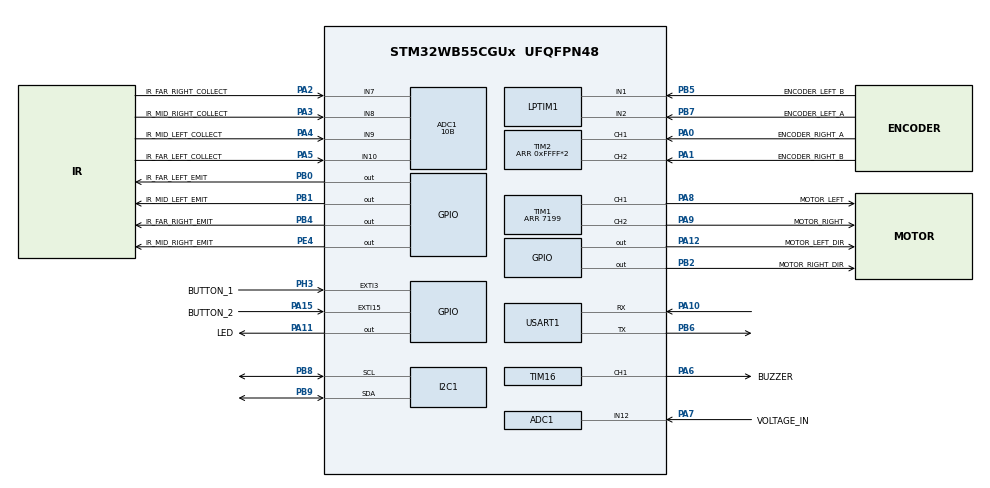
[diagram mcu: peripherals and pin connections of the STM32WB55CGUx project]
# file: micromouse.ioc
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ADC1.Channel-10\#ChannelRegularConversion=ADC_CHANNEL_7
ADC1.Channel-14\#ChannelRegularConversion=ADC_CHANNEL_8
ADC1.Channel-15\#ChannelRegularConversion=ADC_CHANNEL_9
ADC1.Channel-16\#ChannelRegularConversion=ADC_CHANNEL_10
ADC1.Channel-17\#ChannelRegularConversion=ADC_CHANNEL_12
ADC1.NbrOfConversion=5
ADC1.NbrOfConversionFlag=1
ADC1.OffsetNumber-10\#ChannelRegularConversion=ADC_OFFSET_NONE
ADC1.OffsetNumber-14\#ChannelRegularConversion=ADC_OFFSET_NONE
ADC1.OffsetNumber-15\#ChannelRegularConversion=ADC_OFFSET_NONE
ADC1.OffsetNumber-16\#ChannelRegularConversion=ADC_OFFSET_NONE
ADC1.OffsetNumber-17\#ChannelRegularConversion=ADC_OFFSET_NONE
ADC1.Rank-10\#ChannelRegularConversion=1
ADC1.Rank-14\#ChannelRegularConversion=2
ADC1.Rank-15\#ChannelRegularConversion=3
ADC1.Rank-16\#ChannelRegularConversion=4
ADC1.Rank-17\#ChannelRegularConversion=5
ADC1.Resolution=ADC_RESOLUTION_10B
ADC1.SamplingTime-10\#ChannelRegularConversion=ADC_SAMPLETIME_2CYCLES_5
ADC1.SamplingTime-14\#ChannelRegularConversion=ADC_SAMPLETIME_2CYCLES_5
ADC1.SamplingTime-15\#ChannelRegularConversion=ADC_SAMPLETIME_2CYCLES_5
ADC1.SamplingTime-16\#ChannelRegularConversion=ADC_SAMPLETIME_2CYCLES_5
ADC1.SamplingTime-17\#ChannelRegularConversion=ADC_SAMPLETIME_2CYCLES_5
ADC1.master=1
Dma.ADC1.0.Direction=DMA_PERIPH_TO_MEMORY
Dma.ADC1.0.EventEnable=DISABLE
Dma.ADC1.0.Instance=DMA1_Channel2
Dma.ADC1.0.MemDataAlignment=DMA_MDATAALIGN_HALFWORD
Dma.ADC1.0.MemInc=DMA_MINC_ENABLE
Dma.ADC1.0.Mode=DMA_NORMAL
Dma.ADC1.0.PeriphDataAlignment=DMA_PDATAALIGN_HALFWORD
Dma.ADC1.0.PeriphInc=DMA_PINC_DISABLE
Dma.ADC1.0.Polarity=HAL_DMAMUX_REQ_GEN_RISING
Dma.ADC1.0.Priority=DMA_PRIORITY_LOW
Dma.ADC1.0.RequestNumber=1
Dma.ADC1.0.SignalID=NONE
Dma.ADC1.0.SyncEnable=DISABLE
Dma.ADC1.0.SyncPolarity=HAL_DMAMUX_SYNC_NO_EVENT
Dma.ADC1.0.SyncRequestNumber=1
Dma.ADC1.0.SyncSignalID=NONE
Dma.I2C1_RX.1.Direction=DMA_PERIPH_TO_MEMORY
Dma.I2C1_RX.1.EventEnable=DISABLE
Dma.I2C1_RX.1.Instance=DMA1_Channel1
Dma.I2C1_RX.1.MemDataAlignment=DMA_MDATAALIGN_BYTE
Dma.I2C1_RX.1.MemInc=DMA_MINC_ENABLE
Dma.I2C1_RX.1.Mode=DMA_NORMAL
Dma.I2C1_RX.1.PeriphDataAlignment=DMA_PDATAALIGN_BYTE
Dma.I2C1_RX.1.PeriphInc=DMA_PINC_DISABLE
Dma.I2C1_RX.1.Polarity=HAL_DMAMUX_REQ_GEN_RISING
Dma.I2C1_RX.1.Priority=DMA_PRIORITY_HIGH
Dma.I2C1_RX.1.RequestNumber=1
Dma.I2C1_RX.1.SignalID=NONE
Dma.I2C1_RX.1.SyncEnable=DISABLE
Dma.I2C1_RX.1.SyncPolarity=HAL_DMAMUX_SYNC_NO_EVENT
Dma.I2C1_RX.1.SyncRequestNumber=1
Dma.I2C1_RX.1.SyncSignalID=NONE
Dma.Request0=ADC1
Dma.Request1=I2C1_RX
I2C1.I2C_Fall_Time=200
I2C1.I2C_Rise_Time=700
I2C1.Timing=0x30F23E4F
LPTIM1.ULPClockPolarity=LPTIM_CLOCKPOLARITY_RISING
Mcu.Family=STM32WB
Mcu.Name=STM32WB55CGUx
Mcu.Package=UFQFPN48
NVIC.DMA1_Channel1_IRQn=true\:0\:0\:false\:false\:true\:false\:true\:true
NVIC.DMA1_Channel2_IRQn=true\:0\:0\:false\:false\:true\:false\:true\:true
NVIC.EXTI15_10_IRQn=true\:0\:0\:false\:false\:true\:true\:true\:true
NVIC.EXTI3_IRQn=true\:0\:0\:false\:false\:true\:true\:true\:true
NVIC.HSEM_IRQn=true\:0\:0\:false\:false\:true\:false\:true\:true
NVIC.I2C1_ER_IRQn=true\:0\:0\:false\:false\:true\:true\:true\:true
NVIC.I2C1_EV_IRQn=true\:0\:0\:false\:false\:true\:true\:true\:true
NVIC.IPCC_C1_RX_IRQn=true\:0\:0\:false\:false\:true\:true\:true\:true
NVIC.IPCC_C1_TX_IRQn=true\:0\:0\:false\:false\:true\:true\:true\:true
NVIC.PriorityGroup=NVIC_PRIORITYGROUP_4
NVIC.RTC_WKUP_IRQn=true\:0\:0\:false\:false\:true\:true\:true\:true
NVIC.TIM1_TRG_COM_TIM17_IRQn=true\:15\:0\:false\:false\:true\:false\:true\:true
OSC_IN.Mode=HSE-External-Oscillator
OSC_IN.Signal=RCC_OSC_IN
OSC_OUT.Mode=HSE-External-Oscillator
OSC_OUT.Signal=RCC_OSC_OUT
PA0.GPIO_Label=ENCODER_RIGHT_A
PA0.Signal=S_TIM2_CH1
PA1.GPIO_Label=ENCODER_RIGHT_B
PA1.Signal=S_TIM2_CH2
PA10.Mode=Asynchronous
PA10.Signal=USART1_RX
PA11.GPIO_Label=LED
PA11.Signal=GPIO_Output
PA12.GPIO_Label=MOTOR_LEFT_DIR
PA12.Signal=GPIO_Output
PA13.Mode=Trace_Asynchronous_SW
PA13.Signal=SYS_JTMS-SWDIO
PA14.Mode=Trace_Asynchronous_SW
PA14.Signal=SYS_JTCK-SWCLK
PA15.GPIO_Label=BUTTON_2
PA15.Signal=GPXTI15
PA2.GPIO_Label=IR_FAR_RIGHT_COLLECT
PA2.Signal=ADCx_IN7
PA3.GPIO_Label=IR_MID_RIGHT_COLLECT
PA3.Signal=ADCx_IN8
PA4.GPIO_Label=IR_MID_LEFT_COLLECT
PA4.Signal=ADCx_IN9
PA5.GPIO_Label=IR_FAR_LEFT_COLLECT
PA5.Signal=ADCx_IN10
PA6.GPIO_Label=BUZZER
PA6.GPIO_ModeDefaultPP=GPIO_MODE_AF_PP
PA6.GPIO_PuPd=GPIO_NOPULL
PA6.GPIO_Speed=GPIO_SPEED_FREQ_LOW
PA6.Signal=S_TIM16_CH1
PA7.GPIO_Label=VOLTAGE_IN
PA7.Signal=ADCx_IN12
PA8.GPIO_Label=MOTOR_LEFT
PA8.Signal=S_TIM1_CH1
PA9.GPIO_Label=MOTOR_RIGHT
PA9.Signal=S_TIM1_CH2
PB0.GPIO_Label=IR_FAR_LEFT_EMIT
PB0.Signal=GPIO_Output
PB1.GPIO_Label=IR_MID_LEFT_EMIT
PB1.Signal=GPIO_Output
PB2.GPIO_Label=MOTOR_RIGHT_DIR
PB2.Signal=GPIO_Output
PB3.Mode=Trace_Asynchronous_SW
PB3.Signal=SYS_JTDO-SWO
PB4.GPIO_Label=IR_FAR_RIGHT_EMIT
PB4.Signal=GPIO_Output
PB5.GPIO_Label=ENCODER_LEFT_B
PB5.Mode=Encoder_mode_occur1
PB5.Signal=LPTIM1_IN1
PB6.Mode=Asynchronous
PB6.Signal=USART1_TX
PB7.GPIO_Label=ENCODER_LEFT_A
PB7.Mode=Encoder_mode_occur1
PB7.Signal=LPTIM1_IN2
PB8.Mode=I2C
PB8.Signal=I2C1_SCL
PB9.Mode=I2C
PB9.Signal=I2C1_SDA
PC14-OSC32_IN.Mode=LSE-External-Oscillator
PC14-OSC32_IN.Signal=RCC_OSC32_IN
PC15-OSC32_OUT.Mode=LSE-External-Oscillator
PC15-OSC32_OUT.Signal=RCC_OSC32_OUT
PE4.GPIO_Label=IR_MID_RIGHT_EMIT
PE4.Signal=GPIO_Output
PH3-BOOT0.GPIO_Label=BUTTON_1
PH3-BOOT0.Signal=GPXTI3
ProjectManager.HeapSize=0x200
ProjectManager.StackSize=0x400
ProjectManager.TargetToolchain=CMake
RCC.ADCFreq_Value=48000000
RCC.AHB2CLKDivider=RCC_SYSCLK_DIV2
RCC.AHBFreq_Value=64000000
RCC.APB1Freq_Value=64000000
RCC.APB1TimFreq_Value=64000000
RCC.APB2Freq_Value=64000000
RCC.APB2TimFreq_Value=64000000
RCC.APB3Freq_Value=16000000
RCC.CortexFreq_Value=64000000
RCC.HCLKFreq_Value=64000000
RCC.HSE_VALUE=32000000
RCC.HSI48_VALUE=48000000
RCC.HSI_VALUE=16000000
RCC.PLLN=32
RCC.PLLSAI1N=24
RCC.SYSCLKFreq_VALUE=64000000
RCC.SYSCLKSource=RCC_SYSCLKSOURCE_PLLCLK
RCC.USBFreq_Value=48000000
RCC.VCOOutputFreq_Value=128000000
RF1.Mode=RF1_Activate
RF1.Signal=RF_RF1
SH.ADCx_IN10.0=ADC1_IN10,IN10-Single-Ended
SH.ADCx_IN12.0=ADC1_IN12,IN12-Single-Ended
SH.ADCx_IN7.0=ADC1_IN7,IN7-Single-Ended
SH.ADCx_IN8.0=ADC1_IN8,IN8-Single-Ended
SH.ADCx_IN9.0=ADC1_IN9,IN9-Single-Ended
SH.S_TIM16_CH1.0=TIM16_CH1,PWM Generation1 CH1
SH.S_TIM1_CH1.0=TIM1_CH1,PWM Generation1 CH1
SH.S_TIM1_CH2.0=TIM1_CH2,PWM Generation2 CH2
SH.S_TIM2_CH1.0=TIM2_CH1,Encoder_Interface
SH.S_TIM2_CH2.0=TIM2_CH2,Encoder_Interface
STM32_WPAN.AD_TYPE_COMPLETE_LOCAL_NAME=PetersMicroMouse
STM32_WPAN.AD_TYPE_COMPLETE_LOCAL_NAME_LENGTH=17
STM32_WPAN.BT_SIG_HEART_RATE_SENSOR=Disabled
STM32_WPAN.CFG_GAP_DEVICE_NAME=PetersMicroMouse
STM32_WPAN.CFG_GAP_DEVICE_NAME_LENGTH=16
STM32_WPAN.CUSTOM_P2P_SERVER=Disabled
STM32_WPAN.CUSTOM_TEMPLATE=Enabled
STM32_WPAN.INCLUDE_AD_TYPE_COMPLETE_LOCAL_NAME=1
STM32_WPAN.NUMBER_OF_SERVICES=5
STM32_WPAN.SERVICE1_CHAR1_GATT_NOTIFY_ATTRIBUTE_WRITE=GATT_NOTIFY_ATTRIBUTE_WRITE
STM32_WPAN.SERVICE1_CHAR1_GATT_NOTIFY_NOTIFICATION_COMPLETION=\ 
STM32_WPAN.SERVICE1_CHAR1_GATT_NOTIFY_READ_REQ_AND_WAIT_FOR_APPL_RESP=\ 
STM32_WPAN.SERVICE1_CHAR1_GATT_NOTIFY_WRITE_REQ_AND_WAIT_FOR_APPL_RESP=\ 
STM32_WPAN.SERVICE1_CHAR1_LONG_NAME=main_task_writeNotifyChar
STM32_WPAN.SERVICE1_CHAR1_PROP_NOTIFY=CHAR_PROP_NOTIFY
STM32_WPAN.SERVICE1_CHAR1_PROP_WRITE=CHAR_PROP_WRITE
STM32_WPAN.SERVICE1_CHAR1_SHORT_NAME=main_task_char
STM32_WPAN.SERVICE1_CHAR1_VALUE_LENGTH=2
STM32_WPAN.SERVICE1_CHAR2_GATT_NOTIFY_ATTRIBUTE_WRITE=GATT_NOTIFY_ATTRIBUTE_WRITE
STM32_WPAN.SERVICE1_CHAR2_GATT_NOTIFY_READ_REQ_AND_WAIT_FOR_APPL_RESP=\ 
STM32_WPAN.SERVICE1_CHAR2_GATT_NOTIFY_WRITE_REQ_AND_WAIT_FOR_APPL_RESP=\ 
STM32_WPAN.SERVICE1_CHAR2_LONG_NAME=main_command_writeChar
STM32_WPAN.SERVICE1_CHAR2_PROP_WRITE=CHAR_PROP_WRITE
STM32_WPAN.SERVICE1_CHAR2_SHORT_NAME=main_command_char
STM32_WPAN.SERVICE1_CHAR2_UUID=00 01
STM32_WPAN.SERVICE1_CHAR3_GATT_NOTIFY_ATTRIBUTE_WRITE=\ 
STM32_WPAN.SERVICE1_CHAR3_GATT_NOTIFY_READ_REQ_AND_WAIT_FOR_APPL_RESP=\ 
STM32_WPAN.SERVICE1_CHAR3_GATT_NOTIFY_WRITE_REQ_AND_WAIT_FOR_APPL_RESP=\ 
STM32_WPAN.SERVICE1_CHAR3_LONG_NAME=main_error_notifyChar
STM32_WPAN.SERVICE1_CHAR3_PROP_NOTIFY=CHAR_PROP_NOTIFY
STM32_WPAN.SERVICE1_CHAR3_SHORT_NAME=main_error_char
STM32_WPAN.SERVICE1_CHAR3_UUID=00 02
STM32_WPAN.SERVICE1_CHAR3_VALUE_LENGTH=6
STM32_WPAN.SERVICE1_CHAR4_GATT_NOTIFY_READ_REQ_AND_WAIT_FOR_APPL_RESP=\ 
STM32_WPAN.SERVICE1_CHAR4_GATT_NOTIFY_WRITE_REQ_AND_WAIT_FOR_APPL_RESP=\ 
STM32_WPAN.SERVICE1_CHAR4_LONG_NAME=main_song_writeNotifyChar
STM32_WPAN.SERVICE1_CHAR4_PROP_NOTIFY=CHAR_PROP_NOTIFY
STM32_WPAN.SERVICE1_CHAR4_PROP_WRITE=CHAR_PROP_WRITE
STM32_WPAN.SERVICE1_CHAR4_SHORT_NAME=main_song_char
STM32_WPAN.SERVICE1_CHAR4_UUID=00 03
STM32_WPAN.SERVICE1_CHAR5_GATT_NOTIFY_ATTRIBUTE_WRITE=\ 
STM32_WPAN.SERVICE1_CHAR5_GATT_NOTIFY_READ_REQ_AND_WAIT_FOR_APPL_RESP=\ 
STM32_WPAN.SERVICE1_CHAR5_GATT_NOTIFY_WRITE_REQ_AND_WAIT_FOR_APPL_RESP=\ 
STM32_WPAN.SERVICE1_CHAR5_LONG_NAME=main_status_notifyChar
STM32_WPAN.SERVICE1_CHAR5_PROP_NOTIFY=CHAR_PROP_NOTIFY
STM32_WPAN.SERVICE1_CHAR5_SHORT_NAME=main_status_char
STM32_WPAN.SERVICE1_CHAR5_UUID=00 04
STM32_WPAN.SERVICE1_CHAR5_VALUE_LENGTH=5
STM32_WPAN.SERVICE1_LONG_NAME=mainService
STM32_WPAN.SERVICE1_NUMBER_OF_CHARACTERISTICS=5
STM32_WPAN.SERVICE1_SHORT_NAME=mainService
STM32_WPAN.SERVICE2_CHAR1_GATT_NOTIFY_ATTRIBUTE_WRITE=\ 
STM32_WPAN.SERVICE2_CHAR1_GATT_NOTIFY_READ_REQ_AND_WAIT_FOR_APPL_RESP=\ 
STM32_WPAN.SERVICE2_CHAR1_GATT_NOTIFY_WRITE_REQ_AND_WAIT_FOR_APPL_RESP=\ 
STM32_WPAN.SERVICE2_CHAR1_LONG_NAME=vision_rawReadings_notifyChar
STM32_WPAN.SERVICE2_CHAR1_PROP_NOTIFY=CHAR_PROP_NOTIFY
STM32_WPAN.SERVICE2_CHAR1_SHORT_NAME=vision_rawReadings_char
STM32_WPAN.SERVICE2_CHAR1_UUID=00 0A
STM32_WPAN.SERVICE2_CHAR1_VALUE_LENGTH=4*4
STM32_WPAN.SERVICE2_CHAR2_GATT_NOTIFY_ATTRIBUTE_WRITE=\ 
STM32_WPAN.SERVICE2_CHAR2_GATT_NOTIFY_READ_REQ_AND_WAIT_FOR_APPL_RESP=\ 
STM32_WPAN.SERVICE2_CHAR2_GATT_NOTIFY_WRITE_REQ_AND_WAIT_FOR_APPL_RESP=\ 
STM32_WPAN.SERVICE2_CHAR2_LONG_NAME=vision_distances_notifyChar
STM32_WPAN.SERVICE2_CHAR2_PROP_NOTIFY=CHAR_PROP_NOTIFY
STM32_WPAN.SERVICE2_CHAR2_SHORT_NAME=vision_distances_char
STM32_WPAN.SERVICE2_CHAR2_UUID=00 0B
STM32_WPAN.SERVICE2_CHAR2_VALUE_LENGTH=4*4
STM32_WPAN.SERVICE2_LONG_NAME=visionService
STM32_WPAN.SERVICE2_NUMBER_OF_CHARACTERISTICS=2
STM32_WPAN.SERVICE2_SHORT_NAME=visionService
STM32_WPAN.SERVICE2_UUID=00 01
STM32_WPAN.SERVICE3_CHAR1_GATT_NOTIFY_ATTRIBUTE_WRITE=\ 
STM32_WPAN.SERVICE3_CHAR1_GATT_NOTIFY_READ_REQ_AND_WAIT_FOR_APPL_RESP=\ 
STM32_WPAN.SERVICE3_CHAR1_GATT_NOTIFY_WRITE_REQ_AND_WAIT_FOR_APPL_RESP=\ 
STM32_WPAN.SERVICE3_CHAR1_LONG_NAME=drive_data_notifyChar
STM32_WPAN.SERVICE3_CHAR1_PROP_NOTIFY=CHAR_PROP_NOTIFY
STM32_WPAN.SERVICE3_CHAR1_SHORT_NAME=drive_data_char
STM32_WPAN.SERVICE3_CHAR1_UUID=00 0F
STM32_WPAN.SERVICE3_CHAR1_VALUE_LENGTH=6*4
STM32_WPAN.SERVICE3_CHAR2_GATT_NOTIFY_ATTRIBUTE_WRITE=\ 
STM32_WPAN.SERVICE3_CHAR2_GATT_NOTIFY_READ_REQ_AND_WAIT_FOR_APPL_RESP=\ 
STM32_WPAN.SERVICE3_CHAR2_GATT_NOTIFY_WRITE_REQ_AND_WAIT_FOR_APPL_RESP=\ 
STM32_WPAN.SERVICE3_CHAR2_LONG_NAME=drive_imuData_notifyChar
STM32_WPAN.SERVICE3_CHAR2_PROP_NOTIFY=CHAR_PROP_NOTIFY
STM32_WPAN.SERVICE3_CHAR2_SHORT_NAME=drive_imuData_char
STM32_WPAN.SERVICE3_CHAR2_UUID=00 10
STM32_WPAN.SERVICE3_CHAR2_VALUE_LENGTH=6*4
STM32_WPAN.SERVICE3_CHAR3_GATT_NOTIFY_ATTRIBUTE_WRITE=GATT_NOTIFY_ATTRIBUTE_WRITE
STM32_WPAN.SERVICE3_CHAR3_GATT_NOTIFY_READ_REQ_AND_WAIT_FOR_APPL_RESP=\ 
STM32_WPAN.SERVICE3_CHAR3_GATT_NOTIFY_WRITE_REQ_AND_WAIT_FOR_APPL_RESP=\ 
STM32_WPAN.SERVICE3_CHAR3_LONG_NAME=drive_pid_writeNotifyChar
STM32_WPAN.SERVICE3_CHAR3_PROP_NOTIFY=CHAR_PROP_NOTIFY
STM32_WPAN.SERVICE3_CHAR3_PROP_WRITE=CHAR_PROP_WRITE
STM32_WPAN.SERVICE3_CHAR3_SHORT_NAME=drive_pid_char
STM32_WPAN.SERVICE3_CHAR3_UUID=00 11
STM32_WPAN.SERVICE3_CHAR3_VALUE_LENGTH=6*4
STM32_WPAN.SERVICE3_CHAR4_GATT_NOTIFY_ATTRIBUTE_WRITE=GATT_NOTIFY_ATTRIBUTE_WRITE
STM32_WPAN.SERVICE3_CHAR4_GATT_NOTIFY_READ_REQ_AND_WAIT_FOR_APPL_RESP=\ 
STM32_WPAN.SERVICE3_CHAR4_GATT_NOTIFY_WRITE_REQ_AND_WAIT_FOR_APPL_RESP=\ 
STM32_WPAN.SERVICE3_CHAR4_LONG_NAME=drive_chassisSpeeds_writeNotifyChar
STM32_WPAN.SERVICE3_CHAR4_PROP_NOTIFY=CHAR_PROP_NOTIFY
STM32_WPAN.SERVICE3_CHAR4_PROP_WRITE=CHAR_PROP_WRITE
STM32_WPAN.SERVICE3_CHAR4_SHORT_NAME=drive_chassisSpeeds_char
STM32_WPAN.SERVICE3_CHAR4_UUID=00 12
STM32_WPAN.SERVICE3_CHAR4_VALUE_LENGTH=2*4
STM32_WPAN.SERVICE3_LONG_NAME=driveService
STM32_WPAN.SERVICE3_NUMBER_OF_CHARACTERISTICS=4
STM32_WPAN.SERVICE3_SHORT_NAME=driveService
STM32_WPAN.SERVICE3_UUID=00 02
STM32_WPAN.SERVICE4_CHAR1_GATT_NOTIFY_ATTRIBUTE_WRITE=\ 
STM32_WPAN.SERVICE4_CHAR1_GATT_NOTIFY_READ_REQ_AND_WAIT_FOR_APPL_RESP=\ 
STM32_WPAN.SERVICE4_CHAR1_GATT_NOTIFY_WRITE_REQ_AND_WAIT_FOR_APPL_RESP=\ 
STM32_WPAN.SERVICE4_CHAR1_LONG_NAME=maze_cell_notifyChar
STM32_WPAN.SERVICE4_CHAR1_PROP_NOTIFY=CHAR_PROP_NOTIFY
STM32_WPAN.SERVICE4_CHAR1_SHORT_NAME=maze_cell_char
STM32_WPAN.SERVICE4_CHAR1_UUID=00 14
STM32_WPAN.SERVICE4_CHAR1_VALUE_LENGTH=2
STM32_WPAN.SERVICE4_CHAR2_GATT_NOTIFY_ATTRIBUTE_WRITE=\ 
STM32_WPAN.SERVICE4_CHAR2_GATT_NOTIFY_READ_REQ_AND_WAIT_FOR_APPL_RESP=\ 
STM32_WPAN.SERVICE4_CHAR2_GATT_NOTIFY_WRITE_REQ_AND_WAIT_FOR_APPL_RESP=\ 
STM32_WPAN.SERVICE4_CHAR2_LONG_NAME=maze_mousePos_notifyChar
STM32_WPAN.SERVICE4_CHAR2_PROP_NOTIFY=CHAR_PROP_NOTIFY
STM32_WPAN.SERVICE4_CHAR2_SHORT_NAME=maze_mousePos_char
STM32_WPAN.SERVICE4_CHAR2_UUID=00 15
STM32_WPAN.SERVICE4_CHAR2_VALUE_LENGTH=1
STM32_WPAN.SERVICE4_CHAR3_GATT_NOTIFY_ATTRIBUTE_WRITE=GATT_NOTIFY_ATTRIBUTE_WRITE
STM32_WPAN.SERVICE4_CHAR3_GATT_NOTIFY_READ_REQ_AND_WAIT_FOR_APPL_RESP=\ 
STM32_WPAN.SERVICE4_CHAR3_GATT_NOTIFY_WRITE_REQ_AND_WAIT_FOR_APPL_RESP=\ 
STM32_WPAN.SERVICE4_CHAR3_LONG_NAME=drive_pidConstants_writeNotifyChar
STM32_WPAN.SERVICE4_CHAR3_PROP_NOTIFY=CHAR_PROP_NOTIFY
STM32_WPAN.SERVICE4_CHAR3_PROP_WRITE=CHAR_PROP_WRITE
STM32_WPAN.SERVICE4_CHAR3_SHORT_NAME=drive_pidConstants_char
STM32_WPAN.SERVICE4_CHAR3_UUID=00 11
STM32_WPAN.SERVICE4_CHAR3_VALUE_LENGTH=6*sizeof(float)
STM32_WPAN.SERVICE4_CHAR4_GATT_NOTIFY_READ_REQ_AND_WAIT_FOR_APPL_RESP=\ 
STM32_WPAN.SERVICE4_CHAR4_GATT_NOTIFY_WRITE_REQ_AND_WAIT_FOR_APPL_RESP=\ 
STM32_WPAN.SERVICE4_CHAR4_LONG_NAME=drive_chassisSpeeds_writeNotifyChar
STM32_WPAN.SERVICE4_CHAR4_PROP_NOTIFY=CHAR_PROP_NOTIFY
STM32_WPAN.SERVICE4_CHAR4_PROP_WRITE=CHAR_PROP_WRITE
STM32_WPAN.SERVICE4_CHAR4_SHORT_NAME=drive_chassisSpeeds_char
STM32_WPAN.SERVICE4_CHAR4_UUID=00 12
STM32_WPAN.SERVICE4_CHAR4_VALUE_LENGTH=2*sizeof(float)
STM32_WPAN.SERVICE4_LONG_NAME=mazeService
STM32_WPAN.SERVICE4_NUMBER_OF_CHARACTERISTICS=2
STM32_WPAN.SERVICE4_SHORT_NAME=mazeService
STM32_WPAN.SERVICE4_UUID=00 03
STM32_WPAN.SERVICE5_CHAR1_GATT_NOTIFY_ATTRIBUTE_WRITE=\ 
STM32_WPAN.SERVICE5_CHAR1_GATT_NOTIFY_READ_REQ_AND_WAIT_FOR_APPL_RESP=\ 
STM32_WPAN.SERVICE5_CHAR1_GATT_NOTIFY_WRITE_REQ_AND_WAIT_FOR_APPL_RESP=\ 
STM32_WPAN.SERVICE5_CHAR1_LONG_NAME=main_batteryVoltage_notifyChar
STM32_WPAN.SERVICE5_CHAR1_PROP_NOTIFY=CHAR_PROP_NOTIFY
STM32_WPAN.SERVICE5_CHAR1_SHORT_NAME=main_batteryVoltage_char
STM32_WPAN.SERVICE5_CHAR1_UUID=00 05
STM32_WPAN.SERVICE5_CHAR1_VALUE_LENGTH=4
STM32_WPAN.SERVICE5_LONG_NAME=mainService2
STM32_WPAN.SERVICE5_SHORT_NAME=mainService2
STM32_WPAN.SERVICE5_UUID=00 04
TIM1.Channel-PWM\ Generation1\ CH1=TIM_CHANNEL_1
TIM1.Channel-PWM\ Generation2\ CH2=TIM_CHANNEL_2
TIM1.Period=7199
TIM16.Channel=TIM_CHANNEL_1
TIM16.Period=0
TIM16.Prescaler=100
TIM16.Pulse=0
TIM2.EncoderMode=TIM_ENCODERMODE_TI12
TIM2.Period=0xFFFF*2
USART1.VirtualMode-Asynchronous=VM_ASYNC
VP_HSEM_VS_HSEM.Mode=HSEM_Activate
VP_IPCC_VS_IPCC.Mode=IPCC_Activate
VP_MEMORYMAP_VS_MEMORYMAP.Mode=CurAppReg
VP_RTC_VS_RTC_Activate.Mode=RTC_Enabled
VP_RTC_VS_RTC_WakeUp_intern.Mode=WakeUp
VP_SEQUENCER_VS_SEQUENCER.Mode=SEQUENCER_Enabled
VP_STM32_WPAN_VS_BLE_HOST.Mode=STM32_WPAN_Enabled
VP_TIM16_VS_ClockSourceINT.Mode=Enable_Timer
VP_TINY_LPM_VS_TINY_LPM.Mode=TINY_LPM_Enabled
board=custom

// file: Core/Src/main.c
/* USER CODE BEGIN Header */
/**
  ******************************************************************************
  * @file           : main.c
  * @brief          : Main program body
  ******************************************************************************
  * @attention
  *
  * Copyright (c) 2025 STMicroelectronics.
  * All rights reserved.
  *
  * This software is licensed under terms that can be found in the LICENSE file
  * in the root directory of this software component.
  * If no LICENSE file comes with this software, it is provided AS-IS.
  *
  ******************************************************************************
  */
/* USER CODE END Header */
#include "main.h"

/* USER CODE BEGIN Includes */

#include <micromouse/robot/robot.h>

/* USER CODE END Includes */

ADC_HandleTypeDef hadc1;
DMA_HandleTypeDef hdma_adc1;

I2C_HandleTypeDef hi2c1;
DMA_HandleTypeDef hdma_i2c1_rx;

IPCC_HandleTypeDef hipcc;

LPTIM_HandleTypeDef hlptim1;

RTC_HandleTypeDef hrtc;

TIM_HandleTypeDef htim1;
TIM_HandleTypeDef htim2;
TIM_HandleTypeDef htim16;

UART_HandleTypeDef huart1;

void SystemClock_Config(void);
void PeriphCommonClock_Config(void);
static void MX_GPIO_Init(void);
static void MX_DMA_Init(void);
static void MX_TIM16_Init(void);
static void MX_TIM2_Init(void);
static void MX_LPTIM1_Init(void);
static void MX_I2C1_Init(void);
static void MX_IPCC_Init(void);
static void MX_RTC_Init(void);
static void MX_ADC1_Init(void);
static void MX_TIM1_Init(void);
static void MX_USART1_UART_Init(void);
static void MX_RF_Init(void);

int main(void)
{

  /* MCU Configuration--------------------------------------------------------*/

  /* Reset of all peripherals, Initializes the Flash interface and the Systick. */
  HAL_Init();
  /* Config code for STM32_WPAN (HSE Tuning must be done before system clock configuration) */
  MX_APPE_Config();

  /* Configure the system clock */
  SystemClock_Config();

/* Configure the peripherals common clocks */
  PeriphCommonClock_Config();

  /* IPCC initialisation */
  MX_IPCC_Init();

  /* Initialize all configured peripherals */
  MX_GPIO_Init();
  MX_DMA_Init();
  MX_TIM16_Init();
  MX_TIM2_Init();
  MX_LPTIM1_Init();
  MX_I2C1_Init();
  MX_RTC_Init();
  MX_ADC1_Init();
  MX_TIM1_Init();
  MX_USART1_UART_Init();
  MX_RF_Init();
  /* USER CODE BEGIN 2 */

  HAL_TIM_PWM_Start(&htim1, TIM_CHANNEL_1); // Left Motor
  HAL_TIM_PWM_Start(&htim1, TIM_CHANNEL_2); // Right Motor

  HAL_TIM_Encoder_Start(&htim2, TIM_CHANNEL_ALL); // Encoder Right
  HAL_LPTIM_Encoder_Start(&hlptim1, 0xFFFF); // Encoder Left

  HAL_TIM_PWM_Start(&htim16, TIM_CHANNEL_1); // Buzzer

  /* USER CODE END 2 */

  /* Init code for STM32_WPAN */
  MX_APPE_Init();

  /* Infinite loop */
  while (1)
  {
    MX_APPE_Process();

  }
}

void SystemClock_Config(void)
{
  RCC_OscInitTypeDef RCC_OscInitStruct = {0};
  RCC_ClkInitTypeDef RCC_ClkInitStruct = {0};

  /** Configure the main internal regulator output voltage
  */
  __HAL_PWR_VOLTAGESCALING_CONFIG(PWR_REGULATOR_VOLTAGE_SCALE1);

  /** Initializes the RCC Oscillators according to the specified parameters
  * in the RCC_OscInitTypeDef structure.
  */
  RCC_OscInitStruct.OscillatorType = RCC_OSCILLATORTYPE_HSI|RCC_OSCILLATORTYPE_LSI1
                              |RCC_OSCILLATORTYPE_HSE|RCC_OSCILLATORTYPE_MSI;
  RCC_OscInitStruct.HSEState = RCC_HSE_ON;
  RCC_OscInitStruct.HSIState = RCC_HSI_ON;
  RCC_OscInitStruct.MSIState = RCC_MSI_ON;
  RCC_OscInitStruct.HSICalibrationValue = RCC_HSICALIBRATION_DEFAULT;
  RCC_OscInitStruct.MSICalibrationValue = RCC_MSICALIBRATION_DEFAULT;
  RCC_OscInitStruct.MSIClockRange = RCC_MSIRANGE_6;
  RCC_OscInitStruct.LSIState = RCC_LSI_ON;
  RCC_OscInitStruct.PLL.PLLState = RCC_PLL_ON;
  RCC_OscInitStruct.PLL.PLLSource = RCC_PLLSOURCE_MSI;
  RCC_OscInitStruct.PLL.PLLM = RCC_PLLM_DIV1;
  RCC_OscInitStruct.PLL.PLLN = 32;
  RCC_OscInitStruct.PLL.PLLP = RCC_PLLP_DIV2;
  RCC_OscInitStruct.PLL.PLLR = RCC_PLLR_DIV2;
  RCC_OscInitStruct.PLL.PLLQ = RCC_PLLQ_DIV2;
  if (HAL_RCC_OscConfig(&RCC_OscInitStruct) != HAL_OK)
  {
    Error_Handler();
  }

  /** Configure the SYSCLKSource, HCLK, PCLK1 and PCLK2 clocks dividers
  */
  RCC_ClkInitStruct.ClockType = RCC_CLOCKTYPE_HCLK4|RCC_CLOCKTYPE_HCLK2
                              |RCC_CLOCKTYPE_HCLK|RCC_CLOCKTYPE_SYSCLK
                              |RCC_CLOCKTYPE_PCLK1|RCC_CLOCKTYPE_PCLK2;
  RCC_ClkInitStruct.SYSCLKSource = RCC_SYSCLKSOURCE_PLLCLK;
  RCC_ClkInitStruct.AHBCLKDivider = RCC_SYSCLK_DIV1;
  RCC_ClkInitStruct.APB1CLKDivider = RCC_HCLK_DIV1;
  RCC_ClkInitStruct.APB2CLKDivider = RCC_HCLK_DIV1;
  RCC_ClkInitStruct.AHBCLK2Divider = RCC_SYSCLK_DIV2;
  RCC_ClkInitStruct.AHBCLK4Divider = RCC_SYSCLK_DIV1;

  if (HAL_RCC_ClockConfig(&RCC_ClkInitStruct, FLASH_LATENCY_3) != HAL_OK)
  {
    Error_Handler();
  }
}

void PeriphCommonClock_Config(void)
{
  RCC_PeriphCLKInitTypeDef PeriphClkInitStruct = {0};

  /** Initializes the peripherals clock
  */
  PeriphClkInitStruct.PeriphClockSelection = RCC_PERIPHCLK_SMPS|RCC_PERIPHCLK_RFWAKEUP;
  PeriphClkInitStruct.RFWakeUpClockSelection = RCC_RFWKPCLKSOURCE_HSE_DIV1024;
  PeriphClkInitStruct.SmpsClockSelection = RCC_SMPSCLKSOURCE_HSI;
  PeriphClkInitStruct.SmpsDivSelection = RCC_SMPSCLKDIV_RANGE1;

  if (HAL_RCCEx_PeriphCLKConfig(&PeriphClkInitStruct) != HAL_OK)
  {
    Error_Handler();
  }
}

static void MX_ADC1_Init(void)
{

  ADC_ChannelConfTypeDef sConfig = {0};

  /** Common config
  */
  hadc1.Instance = ADC1;
  hadc1.Init.ClockPrescaler = ADC_CLOCK_ASYNC_DIV1;
  hadc1.Init.Resolution = ADC_RESOLUTION_10B;
  hadc1.Init.DataAlign = ADC_DATAALIGN_RIGHT;
  hadc1.Init.ScanConvMode = ADC_SCAN_ENABLE;
  hadc1.Init.EOCSelection = ADC_EOC_SINGLE_CONV;
  hadc1.Init.LowPowerAutoWait = DISABLE;
  hadc1.Init.ContinuousConvMode = DISABLE;
  hadc1.Init.NbrOfConversion = 5;
  hadc1.Init.DiscontinuousConvMode = DISABLE;
  hadc1.Init.ExternalTrigConv = ADC_SOFTWARE_START;
  hadc1.Init.ExternalTrigConvEdge = ADC_EXTERNALTRIGCONVEDGE_NONE;
  hadc1.Init.DMAContinuousRequests = DISABLE;
  hadc1.Init.Overrun = ADC_OVR_DATA_PRESERVED;
  hadc1.Init.OversamplingMode = DISABLE;
  if (HAL_ADC_Init(&hadc1) != HAL_OK)
  {
    Error_Handler();
  }

  /** Configure Regular Channel
  */
  sConfig.Channel = ADC_CHANNEL_7;
  sConfig.Rank = ADC_REGULAR_RANK_1;
  sConfig.SamplingTime = ADC_SAMPLETIME_2CYCLES_5;
  sConfig.SingleDiff = ADC_SINGLE_ENDED;
  sConfig.OffsetNumber = ADC_OFFSET_NONE;
  sConfig.Offset = 0;
  if (HAL_ADC_ConfigChannel(&hadc1, &sConfig) != HAL_OK)
  {
    Error_Handler();
  }

  /** Configure Regular Channel
  */
  sConfig.Channel = ADC_CHANNEL_8;
  sConfig.Rank = ADC_REGULAR_RANK_2;
  if (HAL_ADC_ConfigChannel(&hadc1, &sConfig) != HAL_OK)
  {
    Error_Handler();
  }

  /** Configure Regular Channel
  */
  sConfig.Channel = ADC_CHANNEL_9;
  sConfig.Rank = ADC_REGULAR_RANK_3;
  if (HAL_ADC_ConfigChannel(&hadc1, &sConfig) != HAL_OK)
  {
    Error_Handler();
  }

  /** Configure Regular Channel
  */
  sConfig.Channel = ADC_CHANNEL_10;
  sConfig.Rank = ADC_REGULAR_RANK_4;
  if (HAL_ADC_ConfigChannel(&hadc1, &sConfig) != HAL_OK)
  {
    Error_Handler();
  }

  /** Configure Regular Channel
  */
  sConfig.Channel = ADC_CHANNEL_12;
  sConfig.Rank = ADC_REGULAR_RANK_5;
  if (HAL_ADC_ConfigChannel(&hadc1, &sConfig) != HAL_OK)
  {
    Error_Handler();
  }

}

static void MX_I2C1_Init(void)
{

  hi2c1.Instance = I2C1;
  hi2c1.Init.Timing = 0x30F23E4F;
  hi2c1.Init.OwnAddress1 = 0;
  hi2c1.Init.AddressingMode = I2C_ADDRESSINGMODE_7BIT;
  hi2c1.Init.DualAddressMode = I2C_DUALADDRESS_DISABLE;
  hi2c1.Init.OwnAddress2 = 0;
  hi2c1.Init.OwnAddress2Masks = I2C_OA2_NOMASK;
  hi2c1.Init.GeneralCallMode = I2C_GENERALCALL_DISABLE;
  hi2c1.Init.NoStretchMode = I2C_NOSTRETCH_DISABLE;
  if (HAL_I2C_Init(&hi2c1) != HAL_OK)
  {
    Error_Handler();
  }

  /** Configure Analogue filter
  */
  if (HAL_I2CEx_ConfigAnalogFilter(&hi2c1, I2C_ANALOGFILTER_ENABLE) != HAL_OK)
  {
    Error_Handler();
  }

  /** Configure Digital filter
  */
  if (HAL_I2CEx_ConfigDigitalFilter(&hi2c1, 0) != HAL_OK)
  {
    Error_Handler();
  }

}

static void MX_IPCC_Init(void)
{

  hipcc.Instance = IPCC;
  if (HAL_IPCC_Init(&hipcc) != HAL_OK)
  {
    Error_Handler();
  }

}

static void MX_LPTIM1_Init(void)
{

  hlptim1.Instance = LPTIM1;
  hlptim1.Init.Clock.Source = LPTIM_CLOCKSOURCE_APBCLOCK_LPOSC;
  hlptim1.Init.Clock.Prescaler = LPTIM_PRESCALER_DIV1;
  hlptim1.Init.UltraLowPowerClock.Polarity = LPTIM_CLOCKPOLARITY_RISING;
  hlptim1.Init.UltraLowPowerClock.SampleTime = LPTIM_CLOCKSAMPLETIME_DIRECTTRANSITION;
  hlptim1.Init.Trigger.Source = LPTIM_TRIGSOURCE_SOFTWARE;
  hlptim1.Init.OutputPolarity = LPTIM_OUTPUTPOLARITY_HIGH;
  hlptim1.Init.UpdateMode = LPTIM_UPDATE_IMMEDIATE;
  hlptim1.Init.CounterSource = LPTIM_COUNTERSOURCE_EXTERNAL;
  hlptim1.Init.Input1Source = LPTIM_INPUT1SOURCE_GPIO;
  hlptim1.Init.Input2Source = LPTIM_INPUT2SOURCE_GPIO;
  if (HAL_LPTIM_Init(&hlptim1) != HAL_OK)
  {
    Error_Handler();
  }

}

static void MX_RF_Init(void)
{

}

static void MX_RTC_Init(void)
{

  /** Initialize RTC Only
  */
  hrtc.Instance = RTC;
  hrtc.Init.HourFormat = RTC_HOURFORMAT_24;
  hrtc.Init.AsynchPrediv = CFG_RTC_ASYNCH_PRESCALER;
  hrtc.Init.SynchPrediv = CFG_RTC_SYNCH_PRESCALER;
  hrtc.Init.OutPut = RTC_OUTPUT_DISABLE;
  hrtc.Init.OutPutPolarity = RTC_OUTPUT_POLARITY_HIGH;
  hrtc.Init.OutPutType = RTC_OUTPUT_TYPE_OPENDRAIN;
  hrtc.Init.OutPutRemap = RTC_OUTPUT_REMAP_NONE;
  if (HAL_RTC_Init(&hrtc) != HAL_OK)
  {
    Error_Handler();
  }

  /** Enable the WakeUp
  */
  if (HAL_RTCEx_SetWakeUpTimer_IT(&hrtc, 0, RTC_WAKEUPCLOCK_RTCCLK_DIV16) != HAL_OK)
  {
    Error_Handler();
  }

}

static void MX_TIM1_Init(void)
{

  TIM_MasterConfigTypeDef sMasterConfig = {0};
  TIM_OC_InitTypeDef sConfigOC = {0};
  TIM_BreakDeadTimeConfigTypeDef sBreakDeadTimeConfig = {0};

  htim1.Instance = TIM1;
  htim1.Init.Prescaler = 0;
  htim1.Init.CounterMode = TIM_COUNTERMODE_UP;
  htim1.Init.Period = 7199;
  htim1.Init.ClockDivision = TIM_CLOCKDIVISION_DIV1;
  htim1.Init.RepetitionCounter = 0;
  htim1.Init.AutoReloadPreload = TIM_AUTORELOAD_PRELOAD_DISABLE;
  if (HAL_TIM_PWM_Init(&htim1) != HAL_OK)
  {
    Error_Handler();
  }
  sMasterConfig.MasterOutputTrigger = TIM_TRGO_RESET;
  sMasterConfig.MasterOutputTrigger2 = TIM_TRGO2_RESET;
  sMasterConfig.MasterSlaveMode = TIM_MASTERSLAVEMODE_DISABLE;
  if (HAL_TIMEx_MasterConfigSynchronization(&htim1, &sMasterConfig) != HAL_OK)
  {
    Error_Handler();
  }
  sConfigOC.OCMode = TIM_OCMODE_PWM1;
  sConfigOC.Pulse = 0;
  sConfigOC.OCPolarity = TIM_OCPOLARITY_HIGH;
  sConfigOC.OCNPolarity = TIM_OCNPOLARITY_HIGH;
  sConfigOC.OCFastMode = TIM_OCFAST_DISABLE;
  sConfigOC.OCIdleState = TIM_OCIDLESTATE_RESET;
  sConfigOC.OCNIdleState = TIM_OCNIDLESTATE_RESET;
  if (HAL_TIM_PWM_ConfigChannel(&htim1, &sConfigOC, TIM_CHANNEL_1) != HAL_OK)
  {
    Error_Handler();
  }
  if (HAL_TIM_PWM_ConfigChannel(&htim1, &sConfigOC, TIM_CHANNEL_2) != HAL_OK)
  {
    Error_Handler();
  }
  sBreakDeadTimeConfig.OffStateRunMode = TIM_OSSR_DISABLE;
  sBreakDeadTimeConfig.OffStateIDLEMode = TIM_OSSI_DISABLE;
  sBreakDeadTimeConfig.LockLevel = TIM_LOCKLEVEL_OFF;
  sBreakDeadTimeConfig.DeadTime = 0;
  sBreakDeadTimeConfig.BreakState = TIM_BREAK_DISABLE;
  sBreakDeadTimeConfig.BreakPolarity = TIM_BREAKPOLARITY_HIGH;
  sBreakDeadTimeConfig.BreakFilter = 0;
  sBreakDeadTimeConfig.BreakAFMode = TIM_BREAK_AFMODE_INPUT;
  sBreakDeadTimeConfig.Break2State = TIM_BREAK2_DISABLE;
  sBreakDeadTimeConfig.Break2Polarity = TIM_BREAK2POLARITY_HIGH;
  sBreakDeadTimeConfig.Break2Filter = 0;
  sBreakDeadTimeConfig.Break2AFMode = TIM_BREAK_AFMODE_INPUT;
  sBreakDeadTimeConfig.AutomaticOutput = TIM_AUTOMATICOUTPUT_DISABLE;
  if (HAL_TIMEx_ConfigBreakDeadTime(&htim1, &sBreakDeadTimeConfig) != HAL_OK)
  {
    Error_Handler();
  }
  HAL_TIM_MspPostInit(&htim1);

}

static void MX_TIM2_Init(void)
{

  TIM_Encoder_InitTypeDef sConfig = {0};
  TIM_MasterConfigTypeDef sMasterConfig = {0};

  htim2.Instance = TIM2;
  htim2.Init.Prescaler = 0;
  htim2.Init.CounterMode = TIM_COUNTERMODE_UP;
  htim2.Init.Period = 0xFFFF*2;
  htim2.Init.ClockDivision = TIM_CLOCKDIVISION_DIV1;
  htim2.Init.AutoReloadPreload = TIM_AUTORELOAD_PRELOAD_DISABLE;
  sConfig.EncoderMode = TIM_ENCODERMODE_TI12;
  sConfig.IC1Polarity = TIM_ICPOLARITY_RISING;
  sConfig.IC1Selection = TIM_ICSELECTION_DIRECTTI;
  sConfig.IC1Prescaler = TIM_ICPSC_DIV1;
  sConfig.IC1Filter = 0;
  sConfig.IC2Polarity = TIM_ICPOLARITY_RISING;
  sConfig.IC2Selection = TIM_ICSELECTION_DIRECTTI;
  sConfig.IC2Prescaler = TIM_ICPSC_DIV1;
  sConfig.IC2Filter = 0;
  if (HAL_TIM_Encoder_Init(&htim2, &sConfig) != HAL_OK)
  {
    Error_Handler();
  }
  sMasterConfig.MasterOutputTrigger = TIM_TRGO_RESET;
  sMasterConfig.MasterSlaveMode = TIM_MASTERSLAVEMODE_DISABLE;
  if (HAL_TIMEx_MasterConfigSynchronization(&htim2, &sMasterConfig) != HAL_OK)
  {
    Error_Handler();
  }

}

static void MX_TIM16_Init(void)
{

  TIM_OC_InitTypeDef sConfigOC = {0};
  TIM_BreakDeadTimeConfigTypeDef sBreakDeadTimeConfig = {0};

  htim16.Instance = TIM16;
  htim16.Init.Prescaler = 100;
  htim16.Init.CounterMode = TIM_COUNTERMODE_UP;
  htim16.Init.Period = 0;
  htim16.Init.ClockDivision = TIM_CLOCKDIVISION_DIV1;
  htim16.Init.RepetitionCounter = 0;
  htim16.Init.AutoReloadPreload = TIM_AUTORELOAD_PRELOAD_DISABLE;
  if (HAL_TIM_Base_Init(&htim16) != HAL_OK)
  {
    Error_Handler();
  }
  if (HAL_TIM_PWM_Init(&htim16) != HAL_OK)
  {
    Error_Handler();
  }
  sConfigOC.OCMode = TIM_OCMODE_PWM1;
  sConfigOC.Pulse = 0;
  sConfigOC.OCPolarity = TIM_OCPOLARITY_HIGH;
  sConfigOC.OCNPolarity = TIM_OCNPOLARITY_HIGH;
  sConfigOC.OCFastMode = TIM_OCFAST_DISABLE;
  sConfigOC.OCIdleState = TIM_OCIDLESTATE_RESET;
  sConfigOC.OCNIdleState = TIM_OCNIDLESTATE_RESET;
  if (HAL_TIM_PWM_ConfigChannel(&htim16, &sConfigOC, TIM_CHANNEL_1) != HAL_OK)
  {
    Error_Handler();
  }
  sBreakDeadTimeConfig.OffStateRunMode = TIM_OSSR_DISABLE;
  sBreakDeadTimeConfig.OffStateIDLEMode = TIM_OSSI_DISABLE;
  sBreakDeadTimeConfig.LockLevel = TIM_LOCKLEVEL_OFF;
  sBreakDeadTimeConfig.DeadTime = 0;
  sBreakDeadTimeConfig.BreakState = TIM_BREAK_DISABLE;
  sBreakDeadTimeConfig.BreakPolarity = TIM_BREAKPOLARITY_HIGH;
  sBreakDeadTimeConfig.BreakFilter = 0;
  sBreakDeadTimeConfig.AutomaticOutput = TIM_AUTOMATICOUTPUT_DISABLE;
  if (HAL_TIMEx_ConfigBreakDeadTime(&htim16, &sBreakDeadTimeConfig) != HAL_OK)
  {
    Error_Handler();
  }
  HAL_TIM_MspPostInit(&htim16);

}

static void MX_USART1_UART_Init(void)
{

  huart1.Instance = USART1;
  huart1.Init.BaudRate = 115200;
  huart1.Init.WordLength = UART_WORDLENGTH_8B;
  huart1.Init.StopBits = UART_STOPBITS_1;
  huart1.Init.Parity = UART_PARITY_NONE;
  huart1.Init.Mode = UART_MODE_TX_RX;
  huart1.Init.HwFlowCtl = UART_HWCONTROL_NONE;
  huart1.Init.OverSampling = UART_OVERSAMPLING_16;
  huart1.Init.OneBitSampling = UART_ONE_BIT_SAMPLE_DISABLE;
  huart1.Init.ClockPrescaler = UART_PRESCALER_DIV1;
  huart1.AdvancedInit.AdvFeatureInit = UART_ADVFEATURE_NO_INIT;
  if (HAL_UART_Init(&huart1) != HAL_OK)
  {
    Error_Handler();
  }
  if (HAL_UARTEx_SetTxFifoThreshold(&huart1, UART_TXFIFO_THRESHOLD_1_8) != HAL_OK)
  {
    Error_Handler();
  }
  if (HAL_UARTEx_SetRxFifoThreshold(&huart1, UART_RXFIFO_THRESHOLD_1_8) != HAL_OK)
  {
    Error_Handler();
  }
  if (HAL_UARTEx_DisableFifoMode(&huart1) != HAL_OK)
  {
    Error_Handler();
  }

}

static void MX_DMA_Init(void)
{

  /* DMA controller clock enable */
  __HAL_RCC_DMAMUX1_CLK_ENABLE();
  __HAL_RCC_DMA1_CLK_ENABLE();

  /* DMA interrupt init */
  /* DMA1_Channel1_IRQn interrupt configuration */
  HAL_NVIC_SetPriority(DMA1_Channel1_IRQn, 0, 0);
  HAL_NVIC_EnableIRQ(DMA1_Channel1_IRQn);
  /* DMA1_Channel2_IRQn interrupt configuration */
  HAL_NVIC_SetPriority(DMA1_Channel2_IRQn, 0, 0);
  HAL_NVIC_EnableIRQ(DMA1_Channel2_IRQn);

}

static void MX_GPIO_Init(void)
{
  GPIO_InitTypeDef GPIO_InitStruct = {0};

  /* GPIO Ports Clock Enable */
  __HAL_RCC_GPIOC_CLK_ENABLE();
  __HAL_RCC_GPIOH_CLK_ENABLE();
  __HAL_RCC_GPIOB_CLK_ENABLE();
  __HAL_RCC_GPIOA_CLK_ENABLE();
  __HAL_RCC_GPIOE_CLK_ENABLE();

  /*Configure GPIO pin Output Level */
  HAL_GPIO_WritePin(GPIOB, MOTOR_RIGHT_DIR_Pin|IR_FAR_LEFT_EMIT_Pin|IR_MID_LEFT_EMIT_Pin|IR_FAR_RIGHT_EMIT_Pin, GPIO_PIN_RESET);

  /*Configure GPIO pin Output Level */
  HAL_GPIO_WritePin(IR_MID_RIGHT_EMIT_GPIO_Port, IR_MID_RIGHT_EMIT_Pin, GPIO_PIN_RESET);

  /*Configure GPIO pin Output Level */
  HAL_GPIO_WritePin(GPIOA, LED_Pin|MOTOR_LEFT_DIR_Pin, GPIO_PIN_RESET);

  /*Configure GPIO pin : BUTTON_1_Pin */
  GPIO_InitStruct.Pin = BUTTON_1_Pin;
  GPIO_InitStruct.Mode = GPIO_MODE_IT_RISING;
  GPIO_InitStruct.Pull = GPIO_NOPULL;
  HAL_GPIO_Init(BUTTON_1_GPIO_Port, &GPIO_InitStruct);

  /*Configure GPIO pins : MOTOR_RIGHT_DIR_Pin IR_FAR_LEFT_EMIT_Pin IR_MID_LEFT_EMIT_Pin IR_FAR_RIGHT_EMIT_Pin */
  GPIO_InitStruct.Pin = MOTOR_RIGHT_DIR_Pin|IR_FAR_LEFT_EMIT_Pin|IR_MID_LEFT_EMIT_Pin|IR_FAR_RIGHT_EMIT_Pin;
  GPIO_InitStruct.Mode = GPIO_MODE_OUTPUT_PP;
  GPIO_InitStruct.Pull = GPIO_NOPULL;
  GPIO_InitStruct.Speed = GPIO_SPEED_FREQ_LOW;
  HAL_GPIO_Init(GPIOB, &GPIO_InitStruct);

  /*Configure GPIO pin : IR_MID_RIGHT_EMIT_Pin */
  GPIO_InitStruct.Pin = IR_MID_RIGHT_EMIT_Pin;
  GPIO_InitStruct.Mode = GPIO_MODE_OUTPUT_PP;
  GPIO_InitStruct.Pull = GPIO_NOPULL;
  GPIO_InitStruct.Speed = GPIO_SPEED_FREQ_LOW;
  HAL_GPIO_Init(IR_MID_RIGHT_EMIT_GPIO_Port, &GPIO_InitStruct);

  /*Configure GPIO pins : LED_Pin MOTOR_LEFT_DIR_Pin */
  GPIO_InitStruct.Pin = LED_Pin|MOTOR_LEFT_DIR_Pin;
  GPIO_InitStruct.Mode = GPIO_MODE_OUTPUT_PP;
  GPIO_InitStruct.Pull = GPIO_NOPULL;
  GPIO_InitStruct.Speed = GPIO_SPEED_FREQ_LOW;
  HAL_GPIO_Init(GPIOA, &GPIO_InitStruct);

  /*Configure GPIO pin : BUTTON_2_Pin */
  GPIO_InitStruct.Pin = BUTTON_2_Pin;
  GPIO_InitStruct.Mode = GPIO_MODE_IT_RISING;
  GPIO_InitStruct.Pull = GPIO_NOPULL;
  HAL_GPIO_Init(BUTTON_2_GPIO_Port, &GPIO_InitStruct);

  /* EXTI interrupt init*/
  HAL_NVIC_SetPriority(EXTI3_IRQn, 0, 0);
  HAL_NVIC_EnableIRQ(EXTI3_IRQn);

  HAL_NVIC_SetPriority(EXTI15_10_IRQn, 0, 0);
  HAL_NVIC_EnableIRQ(EXTI15_10_IRQn);

}

void Error_Handler(void)
{
  __disable_irq();
  while (1)
  {
  }
}
